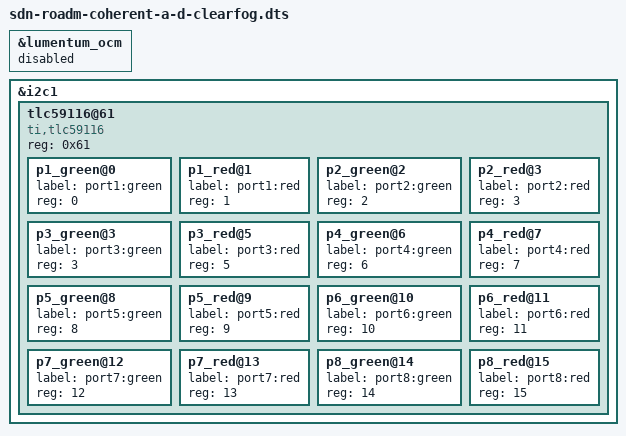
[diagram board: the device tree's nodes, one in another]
#include "sdn-roadm-clearfog.dtsi"

&lumentum_ocm {
	status = "disabled";
};

&i2c1 {
	tlc59116@61 {
		#address-cells = <1>;
		#size-cells = <0>;
		#gpio-cells = <2>;
		compatible = "ti,tlc59116";
		reg = <0x61>;

		p1_green@0 {
			label = "port1:green";
			reg = <0>;
		};
		p1_red@1 {
			label = "port1:red";
			reg = <1>;
		};
		p2_green@2 {
			label = "port2:green";
			reg = <2>;
		};
		p2_red@3 {
			label = "port2:red";
			reg = <3>;
		};
		p3_green@3 {
			label = "port3:green";
			reg = <3>;
		};
		p3_red@5 {
			label = "port3:red";
			reg = <5>;
		};
		p4_green@6 {
			label = "port4:green";
			reg = <6>;
		};
		p4_red@7 {
			label = "port4:red";
			reg = <7>;
		};
		p5_green@8 {
			label = "port5:green";
			reg = <8>;
		};
		p5_red@9 {
			label = "port5:red";
			reg = <9>;
		};
		p6_green@10 {
			label = "port6:green";
			reg = <10>;
		};
		p6_red@11 {
			label = "port6:red";
			reg = <11>;
		};
		p7_green@12 {
			label = "port7:green";
			reg = <12>;
		};
		p7_red@13 {
			label = "port7:red";
			reg = <13>;
		};
		p8_green@14 {
			label = "port8:green";
			reg = <14>;
		};
		p8_red@15 {
			label = "port8:red";
			reg = <15>;
		};
	};

};
